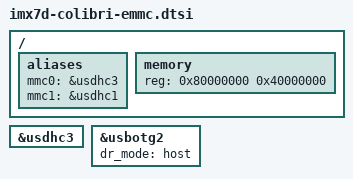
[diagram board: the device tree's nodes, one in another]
/*
 * Copyright (C) 2017 Toradex AG
 *
 * This program is free software; you can redistribute it and/or modify
 * it under the terms of the GNU General Public License version 2 as
 * published by the Free Software Foundation.
 */

#include "imx7d.dtsi"
#include "imx7-colibri.dtsi"

/ {
	aliases {
		/* the following, together with kernel patches, forces a fixed assignment
		   between device id and usdhc controller */
		/* i.e. the eMMC on usdhc3 will be /dev/mmcblk0 */
		mmc0 = &usdhc3; /* eMMC */
		mmc1 = &usdhc1; /* MMC 4bit slot */
	};

	memory {
		reg = <0x80000000 0x40000000>;
	};
};

&usdhc3 {
	status = "okay";
};

&usbotg2 {
	dr_mode = "host";
};
